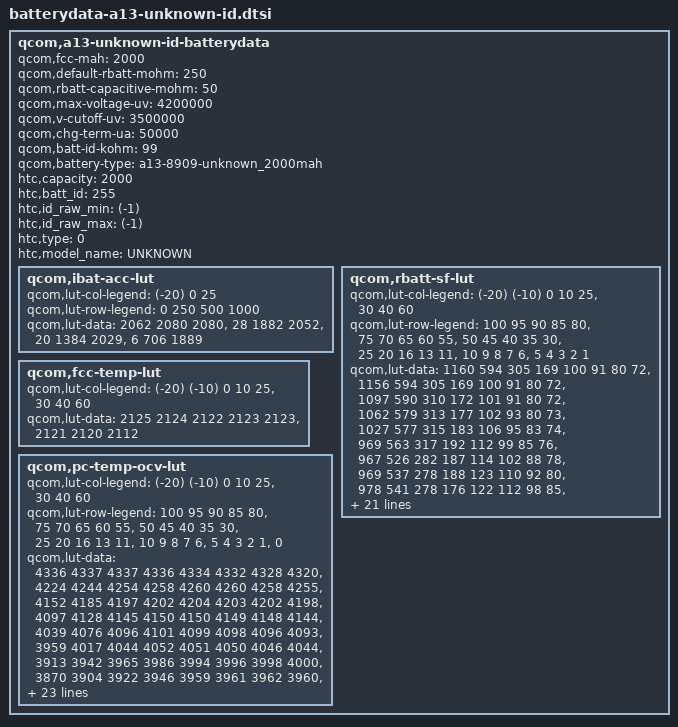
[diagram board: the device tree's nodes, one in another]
/* Copyright (c) 2013, The Linux Foundation. All rights reserved.
 *
 * This program is free software; you can redistribute it and/or modify
 * it under the terms of the GNU General Public License version 2 and
 * only version 2 as published by the Free Software Foundation.
 *
 * This program is distributed in the hope that it will be useful,
 * but WITHOUT ANY WARRANTY; without even the implied warranty of
 * MERCHANTABILITY or FITNESS FOR A PARTICULAR PURPOSE.  See the
 * GNU General Public License for more details.
 */

qcom,a13-unknown-id-batterydata {
	qcom,fcc-mah = <2000>;
	qcom,default-rbatt-mohm = <250>;
	qcom,rbatt-capacitive-mohm = <50>;
	qcom,max-voltage-uv = <4200000>;
	qcom,v-cutoff-uv = <3500000>;
	qcom,chg-term-ua = <50000>;
	qcom,batt-id-kohm = <99>;
	qcom,battery-type = "a13-8909-unknown_2000mah";
	htc,capacity = <2000>;
	htc,batt_id = <255>;
	htc,id_raw_min = <(-1)>;
	htc,id_raw_max = <(-1)>;
	htc,type = <0>;
	htc,model_name = "UNKNOWN";

	qcom,ibat-acc-lut {
		qcom,lut-col-legend = <(-20) 0 25>;
		qcom,lut-row-legend = <0 250 500 1000>;
		qcom,lut-data = <2062 2080 2080>,
				<28 1882 2052>,
				<20 1384 2029>,
				<6 706 1889>;
	};

	qcom,rbatt-sf-lut {
		qcom,lut-col-legend = <(-20) (-10) 0 10 25>,
				<30 40 60>;
		qcom,lut-row-legend = <100 95 90 85 80>,
				<75 70 65 60 55>,
				<50 45 40 35 30>,
				<25 20 16 13 11>,
				<10 9 8 7 6>,
				<5 4 3 2 1>;
		qcom,lut-data = <1160 594 305 169 100 91 80 72>,
				<1156 594 305 169 100 91 80 72>,
				<1097 590 310 172 101 91 80 72>,
				<1062 579 313 177 102 93 80 73>,
				<1027 577 315 183 106 95 83 74>,
				<969 563 317 192 112 99 85 76>,
				<967 526 282 187 114 102 88 78>,
				<969 537 278 188 123 110 92 80>,
				<978 541 278 176 122 112 98 85>,
				<1000 544 276 160 108 101 90 80>,
				<1028 548 276 158 99 90 80 73>,
				<1062 560 279 159 99 91 80 73>,
				<1099 585 287 160 101 92 83 75>,
				<1144 617 304 164 102 94 85 78>,
				<1193 658 321 174 105 95 84 78>,
				<1251 713 337 187 105 94 81 74>,
				<1295 767 338 190 105 94 81 73>,
				<1251 756 343 181 102 93 81 73>,
				<1210 724 338 168 98 90 80 72>,
				<1257 765 356 171 97 89 78 72>,
				<1283 783 369 174 98 90 80 73>,
				<1343 810 382 180 99 91 81 74>,
				<1453 817 397 186 102 93 83 76>,
				<1590 840 414 197 105 95 84 78>,
				<1773 885 426 208 109 99 87 80>,
				<2045 924 434 215 111 99 87 76>,
				<2438 966 447 212 108 97 84 76>,
				<2998 1027 478 219 110 99 86 78>,
				<3948 1183 530 235 120 107 93 85>,
				<6712 1691 609 269 137 124 109 101>;
	};

	qcom,fcc-temp-lut {
		qcom,lut-col-legend = <(-20) (-10) 0 10 25>,
				<30 40 60>;
		qcom,lut-data = <2125 2124 2122 2123 2123>,
				<2121 2120 2112>;
	};

	qcom,pc-temp-ocv-lut {
		qcom,lut-col-legend = <(-20) (-10) 0 10 25>,
				<30 40 60>;
		qcom,lut-row-legend = <100 95 90 85 80>,
				<75 70 65 60 55>,
				<50 45 40 35 30>,
				<25 20 16 13 11>,
				<10 9 8 7 6>,
				<5 4 3 2 1>,
				<0>;
		qcom,lut-data = <4336 4337 4337 4336 4334 4332 4328 4320>,
				<4224 4244 4254 4258 4260 4260 4258 4255>,
				<4152 4185 4197 4202 4204 4203 4202 4198>,
				<4097 4128 4145 4150 4150 4149 4148 4144>,
				<4039 4076 4096 4101 4099 4098 4096 4093>,
				<3959 4017 4044 4052 4051 4050 4046 4044>,
				<3913 3942 3965 3986 3994 3996 3998 4000>,
				<3870 3904 3922 3946 3959 3961 3962 3960>,
				<3838 3873 3892 3907 3920 3922 3924 3922>,
				<3816 3842 3860 3866 3874 3876 3878 3878>,
				<3796 3814 3832 3837 3840 3840 3840 3840>,
				<3778 3791 3808 3814 3816 3817 3818 3816>,
				<3762 3772 3790 3796 3798 3798 3798 3798>,
				<3747 3754 3777 3782 3784 3784 3784 3782>,
				<3734 3740 3764 3772 3772 3771 3769 3764>,
				<3720 3729 3748 3762 3760 3758 3752 3740>,
				<3705 3720 3724 3742 3742 3740 3733 3719>,
				<3688 3712 3710 3720 3720 3718 3712 3699>,
				<3672 3703 3703 3701 3698 3695 3690 3677>,
				<3658 3695 3698 3695 3690 3688 3682 3670>,
				<3650 3690 3696 3692 3688 3686 3681 3670>,
				<3639 3682 3692 3690 3687 3685 3680 3668>,
				<3627 3676 3689 3689 3685 3684 3679 3667>,
				<3612 3664 3685 3687 3684 3682 3677 3665>,
				<3594 3647 3676 3682 3680 3678 3672 3659>,
				<3570 3626 3656 3668 3664 3664 3656 3636>,
				<3539 3594 3624 3633 3626 3622 3615 3592>,
				<3496 3550 3576 3580 3568 3564 3555 3534>,
				<3436 3486 3506 3506 3490 3486 3476 3452>,
				<3332 3382 3396 3391 3370 3362 3350 3320>,
				<3000 3000 3000 3000 3000 3000 3000 3000>;
	};
};
